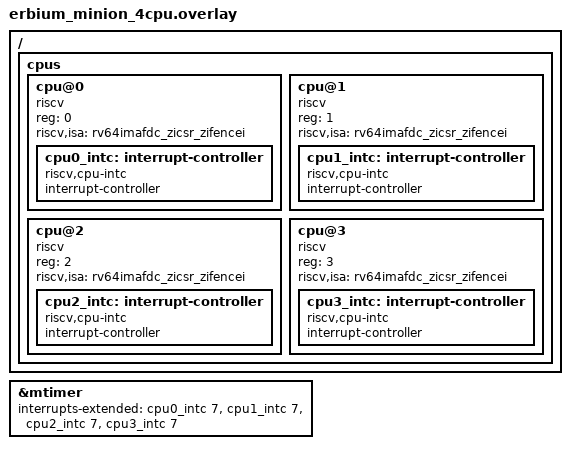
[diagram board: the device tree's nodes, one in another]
/*
 * Copyright (c) 2025 AIFoundry
 * SPDX-License-Identifier: Apache-2.0
 *
 * Device tree overlay for 4-CPU SMP configuration
 */

/ {
	cpus {
		#address-cells = <1>;
		#size-cells = <0>;

		cpu@0 {
			device_type = "cpu";
			compatible = "riscv";
			reg = <0>;
			riscv,isa = "rv64imafdc_zicsr_zifencei";
			status = "okay";
			cpu0_intc: interrupt-controller {
				compatible = "riscv,cpu-intc";
				#address-cells = <0>;
				#interrupt-cells = <1>;
				interrupt-controller;
			};
		};

		cpu@1 {
			device_type = "cpu";
			compatible = "riscv";
			reg = <1>;
			riscv,isa = "rv64imafdc_zicsr_zifencei";
			status = "okay";
			cpu1_intc: interrupt-controller {
				compatible = "riscv,cpu-intc";
				#address-cells = <0>;
				#interrupt-cells = <1>;
				interrupt-controller;
			};
		};

		cpu@2 {
			device_type = "cpu";
			compatible = "riscv";
			reg = <2>;
			riscv,isa = "rv64imafdc_zicsr_zifencei";
			status = "okay";
			cpu2_intc: interrupt-controller {
				compatible = "riscv,cpu-intc";
				#address-cells = <0>;
				#interrupt-cells = <1>;
				interrupt-controller;
			};
		};

		cpu@3 {
			device_type = "cpu";
			compatible = "riscv";
			reg = <3>;
			riscv,isa = "rv64imafdc_zicsr_zifencei";
			status = "okay";
			cpu3_intc: interrupt-controller {
				compatible = "riscv,cpu-intc";
				#address-cells = <0>;
				#interrupt-cells = <1>;
				interrupt-controller;
			};
		};
	};
};

/* Update timer to handle 4 CPUs */
&mtimer {
	interrupts-extended = <&cpu0_intc 7>, <&cpu1_intc 7>,
			      <&cpu2_intc 7>, <&cpu3_intc 7>;
};
